# PIC32MZ2064DAH176 register map
Vendor: Microchip
Registers are 32-bit, read-write, reset 0x0 unless marked. A register's access mark holds for its fields unless they carry their own. Addresses are absolute, and some are shared; only a register's first bit layout is shown; [hi:lo] are bit positions; {n}, {i} and the like mark numbered series.

## lpwr_deep_sleep_ctrl
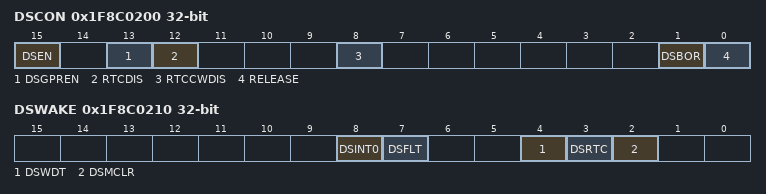
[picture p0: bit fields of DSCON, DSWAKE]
0x1F8C0200 DSCON
  [15] DSEN, [13] DSGPREN, [12] RTCDIS, [8] RTCCWDIS, [1] DSBOR, [0] RELEASE
0x1F8C0210 DSWAKE
  [8] DSINT0, [7] DSFLT, [4] DSWDT, [3] DSRTC, [2] DSMCLR
0x1F8C0220 DSGPR0
  [31:0] DSGPR
{0x1F8C023C+4i} DSGPR{i} (i=1..32)
  [31:0] DSGPR

## PCACHE
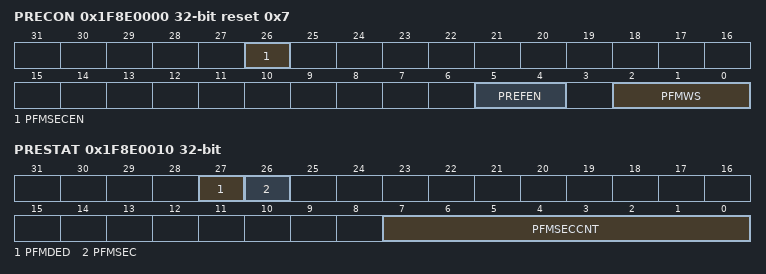
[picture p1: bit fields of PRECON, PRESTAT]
0x1F8E0000 PRECON reset 0x7
  [26] PFMSECEN, [5:4] PREFEN, [2:0] PFMWS
0x1F8E0010 PRESTAT
  [27] PFMDED, [26] PFMSEC, [7:0] PFMSECCNT

## EBI
{0x1F8E1014+4i} EBICS{i} (i=0..3)
  [31:16] CSADDR
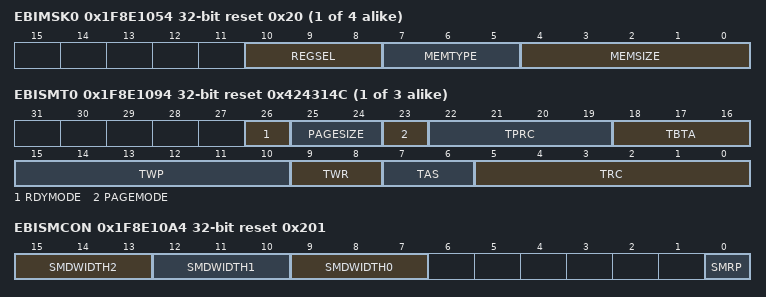
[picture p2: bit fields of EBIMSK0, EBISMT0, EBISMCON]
{0x1F8E1054+4i} EBIMSK{i} reset 0x20 (i=0..3)
  [10:8] REGSEL, [7:5] MEMTYPE, [4:0] MEMSIZE
{0x1F8E1094+4i} EBISMT{i} reset 0x424314C (i=0..2)
  [26] RDYMODE, [25:24] PAGESIZE, [23] PAGEMODE, [22:19] TPRC, [18:16] TBTA, [15:10] TWP, [9:8] TWR, [7:6] TAS, [5:0] TRC
0x1F8E10A0 EBIFTRPD reset 0x201
  [31:0] TRPD
0x1F8E10A4 EBISMCON reset 0x201
  [15:13] SMDWIDTH2, [12:10] SMDWIDTH1, [9:7] SMDWIDTH0, [0] SMRP

## DOS_EIP_00124_usb_hs_otgcore
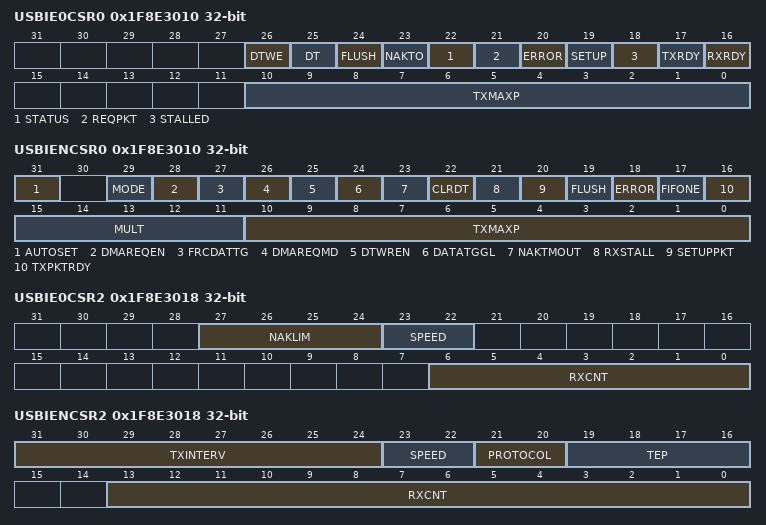
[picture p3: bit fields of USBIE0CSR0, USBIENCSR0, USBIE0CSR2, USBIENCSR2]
0x1F8E3010 USBIE0CSR0
  [26] DTWE, [25] DT, [24] FLUSH, [23] NAKTO, [22] STATUS, [21] REQPKT, [20] ERROR, [19] SETUP, [18] STALLED, [17] TXRDY, [16] RXRDY, [10:0] TXMAXP
0x1F8E3010 USBIENCSR0
  [31] AUTOSET, [29] MODE, [28] DMAREQEN, [27] FRCDATTG, [26] DMAREQMD, [25] DTWREN, [24] DATATGGL, [23] NAKTMOUT, [22] CLRDT, [21] RXSTALL, [20] SETUPPKT, [19] FLUSH, [18] ERROR, [17] FIFONE, [16] TXPKTRDY, [15:11] MULT, [10:0] TXMAXP
0x1F8E3018 USBIE0CSR2
  [27:24] NAKLIM, [23:22] SPEED, [6:0] RXCNT ro
0x1F8E3018 USBIENCSR2
  [31:24] TXINTERV, [23:22] SPEED, [21:20] PROTOCOL, [19:16] TEP, [13:0] RXCNT ro
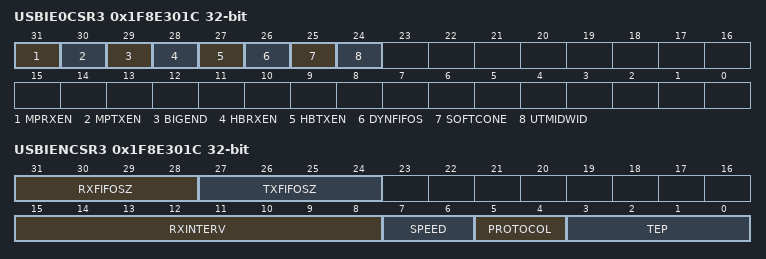
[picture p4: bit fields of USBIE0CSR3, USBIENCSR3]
0x1F8E301C USBIE0CSR3 ro reset not defined — (power-on value xx0xxx10------------------------)
  [31] MPRXEN, [30] MPTXEN, [29] BIGEND, [28] HBRXEN, [27] HBTXEN, [26] DYNFIFOS, [25] SOFTCONE, [24] UTMIDWID
0x1F8E301C USBIENCSR3 reset not defined — (power-on value xxxxxxxx--------0000000000000000)
  [31:28] RXFIFOSZ ro, [27:24] TXFIFOSZ ro, [15:8] RXINTERV, [7:6] SPEED, [5:4] PROTOCOL, [3:0] TEP

## CRYPTO
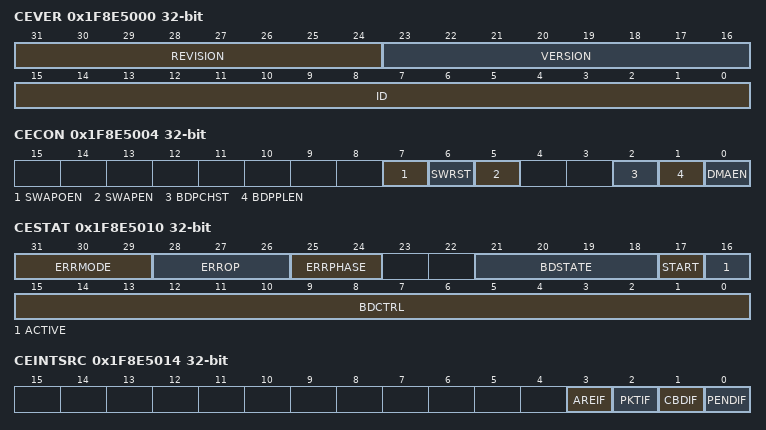
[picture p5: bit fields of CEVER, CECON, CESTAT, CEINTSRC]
0x1F8E5000 CEVER ro reset not defined — (power-on value xxxxxxxxxxxxxxxxxxxxxxxxxxxxxxxx)
  [31:24] REVISION, [23:16] VERSION, [15:0] ID
0x1F8E5004 CECON
  [7] SWAPOEN, [6] SWRST, [5] SWAPEN, [2] BDPCHST, [1] BDPPLEN, [0] DMAEN
0x1F8E5008 CEBDADDR ro
  [31:0] BDPADDR
0x1F8E500C CEBDPADDR ro
  [31:0] BASEADDR
0x1F8E5010 CESTAT ro
  [31:29] ERRMODE, [28:26] ERROP, [25:24] ERRPHASE, [21:18] BDSTATE, [17] START, [16] ACTIVE, [15:0] BDCTRL
0x1F8E5014 CEINTSRC ro
  [3] AREIF, [2] PKTIF, [1] CBDIF, [0] PENDIF
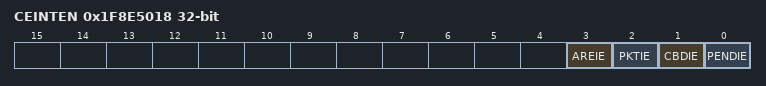
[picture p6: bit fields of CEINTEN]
0x1F8E5018 CEINTEN
  [3] AREIE, [2] PKTIE, [1] CBDIE, [0] PENDIE
0x1F8E501C CEPOLLCON
  [15:0] BDPPLCON
0x1F8E5020 CEHDLEN
  [7:0] HDRLEN
0x1F8E5024 CETRLLEN
  [7:0] TRLRLEN

## RNG
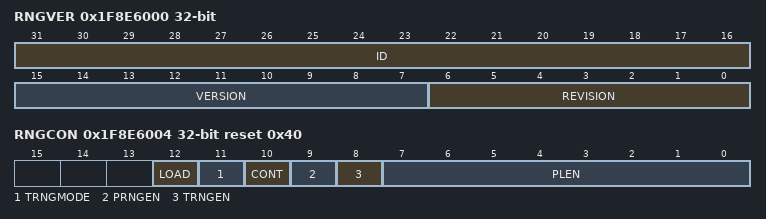
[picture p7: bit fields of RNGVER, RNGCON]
0x1F8E6000 RNGVER ro
  [31:16] ID, [15:7] VERSION, [6:0] REVISION
0x1F8E6004 RNGCON reset 0x40
  [12] LOAD, [11] TRNGMODE, [10] CONT, [9] PRNGEN, [8] TRNGEN, [7:0] PLEN
0x1F8E6008 RNGPOLY1 reset 0xFFFF0000
  [31:0] POLY
0x1F8E600C RNGPOLY2 reset 0xFFFF0000
  [31:0] POLY
0x1F8E6010 RNGNUMGEN1 reset 0xFFFFFFFF
  [31:0] RNG
0x1F8E6014 RNGNUMGEN2 reset 0xFFFFFFFF
  [31:0] RNG
0x1F8E6018 RNGSEED1 ro
  [31:0] SEED
0x1F8E601C RNGSEED2 ro
  [31:0] SEED
0x1F8E6020 RNGCNT
  [6:0] RCNT

## DDR
0x1F8E8000 DDRTSEL
  [7:0] TSEL
0x1F8E8004 DDRMINLIM
  [4:0] MINLIMIT
0x1F8E8008 DDRRQPER
  [7:0] RQPER
0x1F8E800C DDRMINCMD
  [7:0] MINCMD
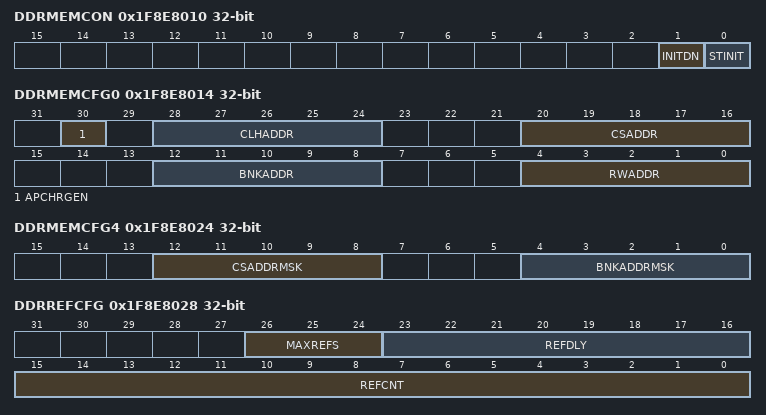
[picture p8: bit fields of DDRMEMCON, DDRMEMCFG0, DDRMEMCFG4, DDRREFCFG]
0x1F8E8010 DDRMEMCON
  [1] INITDN, [0] STINIT
0x1F8E8014 DDRMEMCFG0
  [30] APCHRGEN, [28:24] CLHADDR, [20:16] CSADDR, [12:8] BNKADDR, [4:0] RWADDR
0x1F8E8018 DDRMEMCFG1
  [12:0] RWADDRMSK
0x1F8E801C DDRMEMCFG2
  [12:0] CLADDRHMSK
0x1F8E8020 DDRMEMCFG3
  [12:0] CLADDRLMSK
0x1F8E8024 DDRMEMCFG4
  [12:8] CSADDRMSK, [4:0] BNKADDRMSK
0x1F8E8028 DDRREFCFG
  [26:24] MAXREFS, [23:16] REFDLY, [15:0] REFCNT
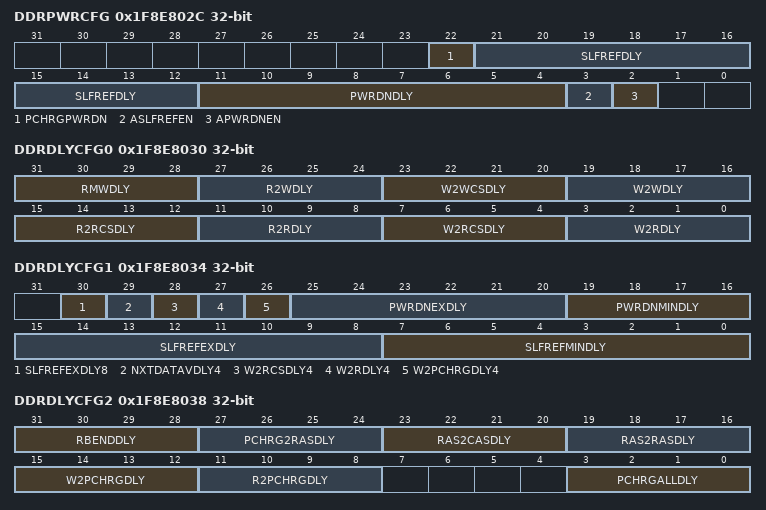
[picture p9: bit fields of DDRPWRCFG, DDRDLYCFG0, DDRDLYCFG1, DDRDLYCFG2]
0x1F8E802C DDRPWRCFG
  [22] PCHRGPWRDN, [21:12] SLFREFDLY, [11:4] PWRDNDLY, [3] ASLFREFEN, [2] APWRDNEN
0x1F8E8030 DDRDLYCFG0
  [31:28] RMWDLY, [27:24] R2WDLY, [23:20] W2WCSDLY, [19:16] W2WDLY, [15:12] R2RCSDLY, [11:8] R2RDLY, [7:4] W2RCSDLY, [3:0] W2RDLY
0x1F8E8034 DDRDLYCFG1
  [30] SLFREFEXDLY8, [29] NXTDATAVDLY4, [28] W2RCSDLY4, [27] W2RDLY4, [26] W2PCHRGDLY4, [25:20] PWRDNEXDLY, [19:16] PWRDNMINDLY, [15:8] SLFREFEXDLY, [7:0] SLFREFMINDLY
0x1F8E8038 DDRDLYCFG2
  [31:28] RBENDDLY, [27:24] PCHRG2RASDLY, [23:20] RAS2CASDLY, [19:16] RAS2RASDLY, [15:12] W2PCHRGDLY, [11:8] R2PCHRGDLY, [3:0] PCHRGALLDLY
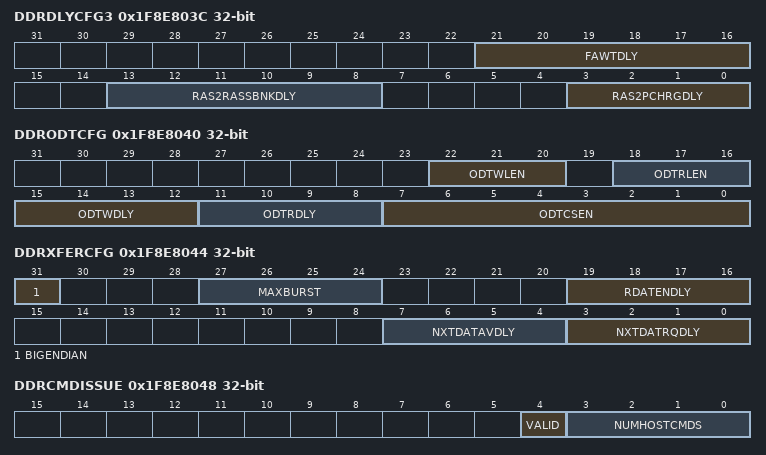
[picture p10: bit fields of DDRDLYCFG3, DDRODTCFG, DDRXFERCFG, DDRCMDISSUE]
0x1F8E803C DDRDLYCFG3
  [21:16] FAWTDLY, [13:8] RAS2RASSBNKDLY, [3:0] RAS2PCHRGDLY
0x1F8E8040 DDRODTCFG
  [22:20] ODTWLEN, [18:16] ODTRLEN, [15:12] ODTWDLY, [11:8] ODTRDLY, [7:0] ODTCSEN
0x1F8E8044 DDRXFERCFG
  [31] BIGENDIAN, [27:24] MAXBURST, [19:16] RDATENDLY, [7:4] NXTDATAVDLY, [3:0] NXTDATRQDLY
0x1F8E8048 DDRCMDISSUE
  [4] VALID, [3:0] NUMHOSTCMDS
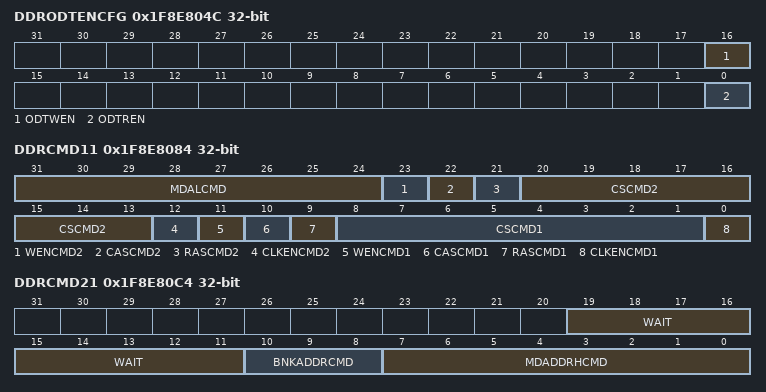
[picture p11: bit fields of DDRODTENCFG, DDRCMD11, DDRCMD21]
0x1F8E804C DDRODTENCFG
  [16] ODTWEN, [0] ODTREN
0x1F8E8050 DDRMEMWIDTH
  [3] HALFRATE
0x1F8E8084 DDRCMD11 reset not defined — (power-on value xxxxxxxxxxxxxxxxxxxx000000000000)
  [31:24] MDALCMD, [23] WENCMD2, [22] CASCMD2, [21] RASCMD2, [20:13] CSCMD2, [12] CLKENCMD2, [11] WENCMD1, [10] CASCMD1, [9] RASCMD1, [8:1] CSCMD1, [0] CLKENCMD1
0x1F8E80C4 DDRCMD21
  [19:11] WAIT, [10:8] BNKADDRCMD, [7:0] MDADDRHCMD
